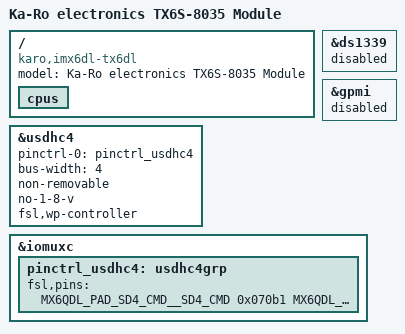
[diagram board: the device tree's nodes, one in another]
// SPDX-License-Identifier: (GPL-2.0-only OR MIT)
/*
 * Copyright 2015-2017 Lothar Waßmann <LW@KARO-electronics.de>
 */

/dts-v1/;
#include "imx6dl.dtsi"
#include "imx6qdl-tx6.dtsi"
#include "imx6qdl-tx6-lcd.dtsi"

/ {
	model = "Ka-Ro electronics TX6S-8035 Module";
	compatible = "karo,imx6dl-tx6dl", "fsl,imx6dl";

	cpus {
		/delete-node/ cpu@1;
	};
};

&ds1339 {
	status = "disabled";
};

&gpmi {
	status = "disabled";
};

&usdhc4 {
	pinctrl-names = "default";
	pinctrl-0 = <&pinctrl_usdhc4>;
	bus-width = <4>;
	non-removable;
	no-1-8-v;
	fsl,wp-controller;
	status = "okay";
};

&iomuxc {
	pinctrl_usdhc4: usdhc4grp {
		fsl,pins = <
			MX6QDL_PAD_SD4_CMD__SD4_CMD		0x070b1
			MX6QDL_PAD_SD4_CLK__SD4_CLK		0x070b1
			MX6QDL_PAD_SD4_DAT0__SD4_DATA0		0x070b1
			MX6QDL_PAD_SD4_DAT1__SD4_DATA1		0x070b1
			MX6QDL_PAD_SD4_DAT2__SD4_DATA2		0x070b1
			MX6QDL_PAD_SD4_DAT3__SD4_DATA3		0x070b1
			MX6QDL_PAD_NANDF_ALE__SD4_RESET		0x0b0b1
		>;
	};
};
